VERSION "1.0"

NS_ :

BS_:

BU_: ECM TCM ABS

VAL_TABLE_ GearTable 0 "Neutral" 1 "First" 2 "Second" 3 "Third" ;

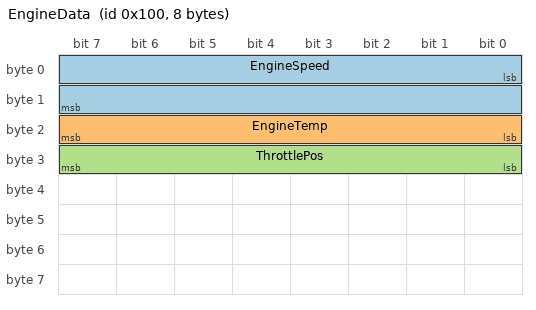
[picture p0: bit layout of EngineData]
BO_ 256 EngineData: 8 ECM
 SG_ EngineSpeed : 0|16@1+ (0.25,0) [0|16383.75] "rpm" TCM,ABS
 SG_ EngineTemp : 16|8@1+ (1,-40) [-40|215] "degC" TCM
 SG_ ThrottlePos : 24|8@1+ (0.4,0) [0|102] "%" TCM

BO_ 512 TransmissionData: 6 TCM
 SG_ CurrentGear : 0|4@1+ (1,0) [0|15] "" ECM
 SG_ OutputSpeed : 8|16@1+ (0.125,0) [0|8191.875] "rpm" ECM,ABS

CM_ SG_ 256 EngineSpeed "Engine speed from crankshaft sensor";

BA_DEF_ BO_ "GenMsgCycleTime" INT 0 65535;
BA_ "GenMsgCycleTime" BO_ 256 10;

VAL_ 512 CurrentGear 0 "Neutral" 1 "First" 2 "Second" 3 "Third" ;
